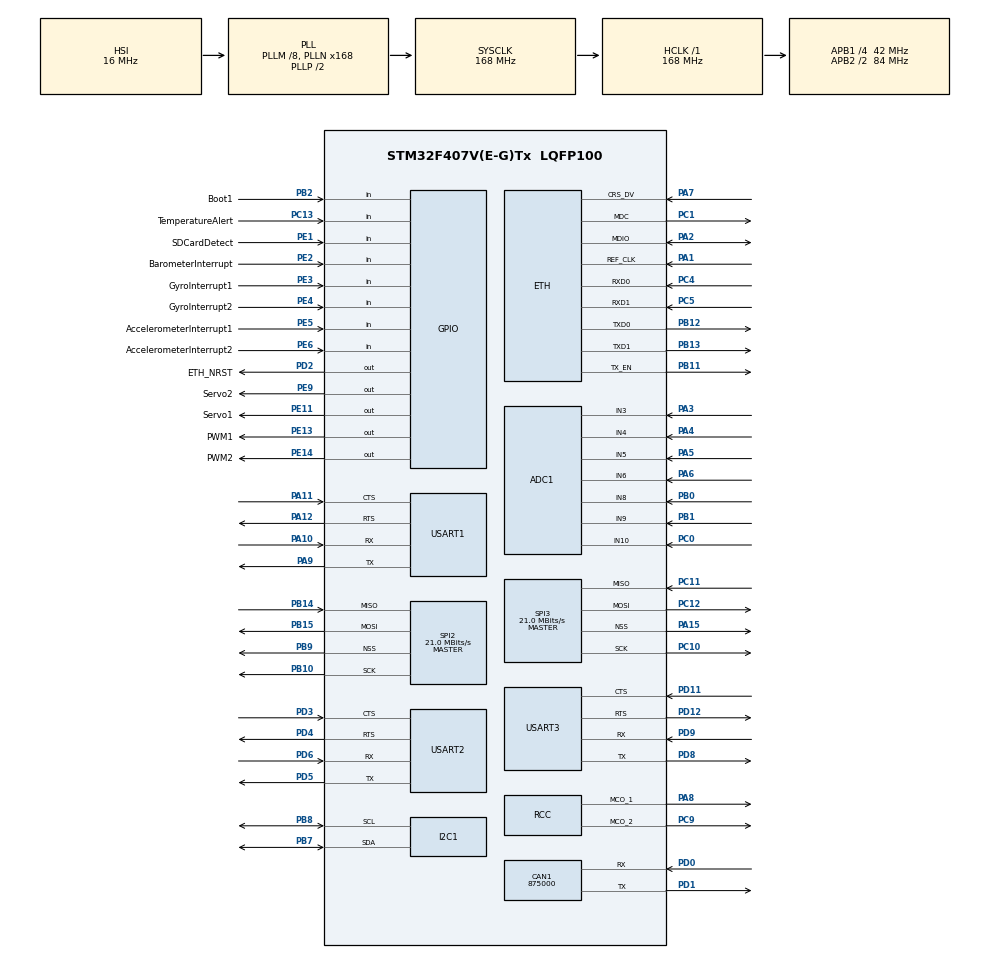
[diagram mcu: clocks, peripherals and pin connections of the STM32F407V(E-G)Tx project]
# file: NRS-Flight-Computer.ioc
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ADC1.Channel-0\#ChannelRegularConversion=ADC_CHANNEL_10
ADC1.NbrOfConversionFlag=1
ADC1.Rank-0\#ChannelRegularConversion=1
ADC1.SamplingTime-0\#ChannelRegularConversion=ADC_SAMPLETIME_3CYCLES
ADC1.master=1
CAN1.CalculateBaudRate=875000
CAN1.CalculateTimeBit=1142
CAN1.CalculateTimeQuantum=380.95238095238096
ETH.MediaInterface=HAL_ETH_RMII_MODE
Mcu.Family=STM32F4
Mcu.Name=STM32F407V(E-G)Tx
Mcu.Package=LQFP100
NVIC.PriorityGroup=NVIC_PRIORITYGROUP_4
PA1.Mode=RMII
PA1.Signal=ETH_REF_CLK
PA10.Mode=Asynchronous
PA10.Signal=USART1_RX
PA11.Mode=CTS_RTS
PA11.Signal=USART1_CTS
PA12.Mode=CTS_RTS
PA12.Signal=USART1_RTS
PA13.Mode=Trace_Asynchronous_SW
PA13.Signal=SYS_JTMS-SWDIO
PA14.Mode=Trace_Asynchronous_SW
PA14.Signal=SYS_JTCK-SWCLK
PA15.Mode=NSS_Signal_Hard_Output
PA15.Signal=SPI3_NSS
PA2.Mode=RMII
PA2.Signal=ETH_MDIO
PA3.Signal=ADCx_IN3
PA4.Signal=ADCx_IN4
PA5.Signal=ADCx_IN5
PA6.Signal=ADCx_IN6
PA7.Mode=RMII
PA7.Signal=ETH_CRS_DV
PA8.Mode=Clock-out-1
PA8.Signal=RCC_MCO_1
PA9.Mode=Asynchronous
PA9.Signal=USART1_TX
PB0.Signal=ADCx_IN8
PB1.Signal=ADCx_IN9
PB10.Mode=Full_Duplex_Master
PB10.Signal=SPI2_SCK
PB11.Mode=RMII
PB11.Signal=ETH_TX_EN
PB12.Mode=RMII
PB12.Signal=ETH_TXD0
PB13.Mode=RMII
PB13.Signal=ETH_TXD1
PB14.Mode=Full_Duplex_Master
PB14.Signal=SPI2_MISO
PB15.Mode=Full_Duplex_Master
PB15.Signal=SPI2_MOSI
PB2.GPIO_Label=Boot1
PB2.Signal=GPIO_Input
PB3.Mode=Trace_Asynchronous_SW
PB3.Signal=SYS_JTDO-SWO
PB7.Mode=I2C
PB7.Signal=I2C1_SDA
PB8.Mode=I2C
PB8.Signal=I2C1_SCL
PB9.Mode=NSS_Signal_Hard_Output
PB9.Signal=SPI2_NSS
PC0.Signal=ADCx_IN10
PC1.Mode=RMII
PC1.Signal=ETH_MDC
PC10.Mode=Full_Duplex_Master
PC10.Signal=SPI3_SCK
PC11.Mode=Full_Duplex_Master
PC11.Signal=SPI3_MISO
PC12.Mode=Full_Duplex_Master
PC12.Signal=SPI3_MOSI
PC13-ANTI_TAMP.GPIO_Label=TemperatureAlert
PC13-ANTI_TAMP.Signal=GPIO_Input
PC4.Mode=RMII
PC4.Signal=ETH_RXD0
PC5.Mode=RMII
PC5.Signal=ETH_RXD1
PC9.Mode=Clock-out-2
PC9.Signal=RCC_MCO_2
PD0.Mode=CAN_Activate
PD0.Signal=CAN1_RX
PD1.Mode=CAN_Activate
PD1.Signal=CAN1_TX
PD11.Mode=CTS_RTS
PD11.Signal=USART3_CTS
PD12.Mode=CTS_RTS
PD12.Signal=USART3_RTS
PD2.GPIO_Label=ETH_NRST
PD2.Signal=GPIO_Output
PD3.Mode=CTS_RTS
PD3.Signal=USART2_CTS
PD4.Mode=CTS_RTS
PD4.Signal=USART2_RTS
PD5.Mode=Asynchronous
PD5.Signal=USART2_TX
PD6.Mode=Asynchronous
PD6.Signal=USART2_RX
PD8.Mode=Asynchronous
PD8.Signal=USART3_TX
PD9.Mode=Asynchronous
PD9.Signal=USART3_RX
PE1.GPIO_Label=SDCardDetect
PE1.Signal=GPIO_Input
PE11.GPIO_Label=Servo1
PE11.Signal=GPIO_Output
PE13.GPIO_Label=PWM1
PE13.Signal=GPIO_Output
PE14.GPIO_Label=PWM2
PE14.Signal=GPIO_Output
PE2.GPIO_Label=BarometerInterrupt
PE2.Signal=GPIO_Input
PE3.GPIO_Label=GyroInterrupt1
PE3.Signal=GPIO_Input
PE4.GPIO_Label=GyroInterrupt2
PE4.Signal=GPIO_Input
PE5.GPIO_Label=AccelerometerInterrupt1
PE5.Signal=GPIO_Input
PE6.GPIO_Label=AccelerometerInterrupt2
PE6.Signal=GPIO_Input
PE9.GPIO_Label=Servo2
PE9.Signal=GPIO_Output
PH0-OSC_IN.Mode=HSE-External-Oscillator
PH0-OSC_IN.Signal=RCC_OSC_IN
PH1-OSC_OUT.Mode=HSE-External-Oscillator
PH1-OSC_OUT.Signal=RCC_OSC_OUT
ProjectManager.HeapSize=0x200
ProjectManager.StackSize=0x400
ProjectManager.TargetToolchain=Makefile
RCC.48MHZClocksFreq_Value=48000000
RCC.AHBFreq_Value=168000000
RCC.APB1CLKDivider=RCC_HCLK_DIV4
RCC.APB1Freq_Value=42000000
RCC.APB1TimFreq_Value=84000000
RCC.APB2CLKDivider=RCC_HCLK_DIV2
RCC.APB2Freq_Value=84000000
RCC.APB2TimFreq_Value=168000000
RCC.CortexFreq_Value=168000000
RCC.HCLKFreq_Value=168000000
RCC.HSE_VALUE=25000000
RCC.HSI_VALUE=16000000
RCC.LSE_VALUE=32768
RCC.PLLM=8
RCC.PLLN=168
RCC.PLLQ=7
RCC.RCC_MCO1Source=RCC_MCO1SOURCE_HSE
RCC.SYSCLKFreq_VALUE=168000000
RCC.SYSCLKSource=RCC_SYSCLKSOURCE_PLLCLK
RCC.VCOOutputFreq_Value=336000000
SH.ADCx_IN10.0=ADC1_IN10,IN10
SH.ADCx_IN3.0=ADC1_IN3,IN3
SH.ADCx_IN4.0=ADC1_IN4,IN4
SH.ADCx_IN5.0=ADC1_IN5,IN5
SH.ADCx_IN6.0=ADC1_IN6,IN6
SH.ADCx_IN8.0=ADC1_IN8,IN8
SH.ADCx_IN9.0=ADC1_IN9,IN9
SPI2.CalculateBaudRate=21.0 MBits/s
SPI2.Direction=SPI_DIRECTION_2LINES
SPI2.Mode=SPI_MODE_MASTER
SPI2.VirtualNSS=VM_NSSHARD
SPI2.VirtualType=VM_MASTER
SPI3.CalculateBaudRate=21.0 MBits/s
SPI3.Direction=SPI_DIRECTION_2LINES
SPI3.Mode=SPI_MODE_MASTER
SPI3.VirtualNSS=VM_NSSHARD
SPI3.VirtualType=VM_MASTER
USART1.VirtualMode=VM_ASYNC
USART2.VirtualMode=VM_ASYNC
USART3.VirtualMode=VM_ASYNC
VP_CRC_VS_CRC.Mode=CRC_Activate
VP_RNG_VS_RNG.Mode=RNG_Activate
board=custom

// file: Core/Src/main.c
/* USER CODE BEGIN Header */
/**
  ******************************************************************************
  * @file           : main.c
  * @brief          : Main program body
  ******************************************************************************
  * @attention
  *
  * Copyright (c) 2024 STMicroelectronics.
  * All rights reserved.
  *
  * This software is licensed under terms that can be found in the LICENSE file
  * in the root directory of this software component.
  * If no LICENSE file comes with this software, it is provided AS-IS.
  *
  ******************************************************************************
  */
/* USER CODE END Header */
#include "main.h"
#include "adc.h"
#include "can.h"
#include "crc.h"
#include "eth.h"
#include "i2c.h"
#include "rng.h"
#include "spi.h"
#include "usart.h"
#include "gpio.h"
#include <Project/main.hpp>

void SystemClock_Config(void);

int main(void)
{

  /* MCU Configuration--------------------------------------------------------*/

  /* Reset of all peripherals, Initializes the Flash interface and the Systick. */
  HAL_Init();

  /* Configure the system clock */
  SystemClock_Config();

  /* Initialize all configured peripherals */
  MX_GPIO_Init();
  MX_ADC1_Init();
  MX_CAN1_Init();
  MX_CRC_Init();
  //MX_ETH_Init();
  MX_I2C1_Init();
  MX_RNG_Init();
  MX_SPI2_Init();
  MX_SPI3_Init();
  MX_USART1_UART_Init();
  MX_USART2_UART_Init();
  MX_USART3_UART_Init();
  /* USER CODE BEGIN 2 */
  init();
  /* USER CODE END 2 */

  /* Infinite loop */
  while (1)
  {
    loop();
  }
}

void SystemClock_Config(void)
{
  RCC_OscInitTypeDef RCC_OscInitStruct = {0};
  RCC_ClkInitTypeDef RCC_ClkInitStruct = {0};

  /** Configure the main internal regulator output voltage
  */
  __HAL_RCC_PWR_CLK_ENABLE();
  __HAL_PWR_VOLTAGESCALING_CONFIG(PWR_REGULATOR_VOLTAGE_SCALE1);

  /** Initializes the RCC Oscillators according to the specified parameters
  * in the RCC_OscInitTypeDef structure.
  */
  RCC_OscInitStruct.OscillatorType = RCC_OSCILLATORTYPE_HSI|RCC_OSCILLATORTYPE_HSE;
  RCC_OscInitStruct.HSEState = RCC_HSE_ON;
  RCC_OscInitStruct.HSIState = RCC_HSI_ON;
  RCC_OscInitStruct.HSICalibrationValue = RCC_HSICALIBRATION_DEFAULT;
  RCC_OscInitStruct.PLL.PLLState = RCC_PLL_ON;
  RCC_OscInitStruct.PLL.PLLSource = RCC_PLLSOURCE_HSI;
  RCC_OscInitStruct.PLL.PLLM = 8;
  RCC_OscInitStruct.PLL.PLLN = 168;
  RCC_OscInitStruct.PLL.PLLP = RCC_PLLP_DIV2;
  RCC_OscInitStruct.PLL.PLLQ = 7;
  if (HAL_RCC_OscConfig(&RCC_OscInitStruct) != HAL_OK)
  {
    Error_Handler();
  }

  /** Initializes the CPU, AHB and APB buses clocks
  */
  RCC_ClkInitStruct.ClockType = RCC_CLOCKTYPE_HCLK|RCC_CLOCKTYPE_SYSCLK
                              |RCC_CLOCKTYPE_PCLK1|RCC_CLOCKTYPE_PCLK2;
  RCC_ClkInitStruct.SYSCLKSource = RCC_SYSCLKSOURCE_PLLCLK;
  RCC_ClkInitStruct.AHBCLKDivider = RCC_SYSCLK_DIV1;
  RCC_ClkInitStruct.APB1CLKDivider = RCC_HCLK_DIV4;
  RCC_ClkInitStruct.APB2CLKDivider = RCC_HCLK_DIV2;

  if (HAL_RCC_ClockConfig(&RCC_ClkInitStruct, FLASH_LATENCY_5) != HAL_OK)
  {
    Error_Handler();
  }
  HAL_RCC_MCOConfig(RCC_MCO1, RCC_MCO1SOURCE_HSE, RCC_MCODIV_1);
  HAL_RCC_MCOConfig(RCC_MCO2, RCC_MCO2SOURCE_SYSCLK, RCC_MCODIV_1);
}

void Error_Handler(void)
{
  __disable_irq();
  while (1)
  {
  }
}
